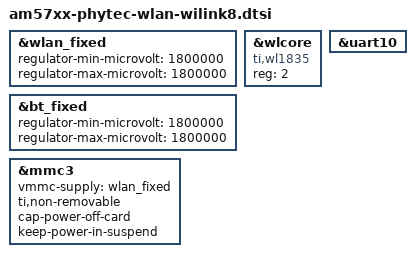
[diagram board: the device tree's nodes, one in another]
/*
 * Copyright (C) 2015 Russell Robinson <rrobinson@phytec.com>
 * Copyright (C) PHYTEC America, LLC.
 *
 * This program is free software; you can redistribute it and/or modify
 * it under the terms of the GNU General Public License version 2 as
 * published by the Free Software Foundation.
 */

/*
 * The board specific DTS file have to:
 *  - Specify WL_EN (wlan_fixed), WL_IRQ (wlcore), and
      BL_EN (bt_fixed) signals for wifi and bluetooth operation
 *  - Mux the WL_EN, WL_IRQ, and BL_EN pins
 *  - Set the node statuses to "okay" in the dts
*/

&wlan_fixed {
	status = "okay";

	regulator-min-microvolt = <1800000>;
	regulator-max-microvolt = <1800000>;
};

&bt_fixed {
	status = "okay";

	regulator-min-microvolt = <1800000>;
	regulator-max-microvolt = <1800000>;
};

&mmc3 {
	status = "okay";

	vmmc-supply = <&wlan_fixed>;
        ti,non-removable;
        cap-power-off-card;
        keep-power-in-suspend;
};

&wlcore {
	status = "okay";
	compatible = "ti,wl1835";

	reg = <2>;
};

&uart10 {
	status = "okay";
};
